AUTOSAR XML (schema 00044)
package /ComponentTypes
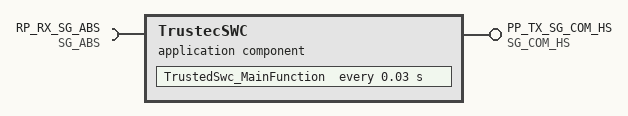
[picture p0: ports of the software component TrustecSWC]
  application sw component type TrustecSWC
    require port RP_RX_SG_ABS: nonqueued-receiver-com-spec{data-element=RP_SR_TX_SG_ABS, filter=data-filter-type=ALWAYS, handle-never-received=true, init-value=fields=[Airbag:0, Alive_101:0, CRC_101:0, VehicleSpeedABS:0]}, required-interface=SG_ABS
    provide port PP_TX_SG_COM_HS: nonqueued-sender-com-spec{data-element=SG_COM_HS, transmission-acknowledge=timeout=0, init-value=fields=[Alive_200:0, Battery_Voltage:0, CRC_200:0]}, provided-interface=SG_COM_HS
    behavior TrustecSWC_InternalBehavior
      timing event TMT_TrustedSwc_MainFunction: start-on-event=TrustedSwc_MainFunction, period=0.03
      port-api-options:
        enable-take-address=false, error-handling=TRANSFORMER-ERROR-HANDLING, indirect-api=false, port=RP_RX_SG_ABS
        enable-take-address=false, error-handling=TRANSFORMER-ERROR-HANDLING, indirect-api=false, port=PP_TX_SG_COM_HS
      runnable TrustedSwc_MainFunction
        data-receive-point-by-arguments:
          access REC_RP_RX_SG_ABS_RP_SR_TX_SG_ABS: accessed-variable=RP_RX_SG_ABS.RP_SR_TX_SG_ABS
        data-send-points:
          access SEND_PP_TX_SG_COM_HSSG_COM_HS_SG_COM_HS: accessed-variable=PP_TX_SG_COM_HS.SG_COM_HS
  swc implementation TrustecSWC_Implementation: behavior=TrustecSWC_InternalBehavior
